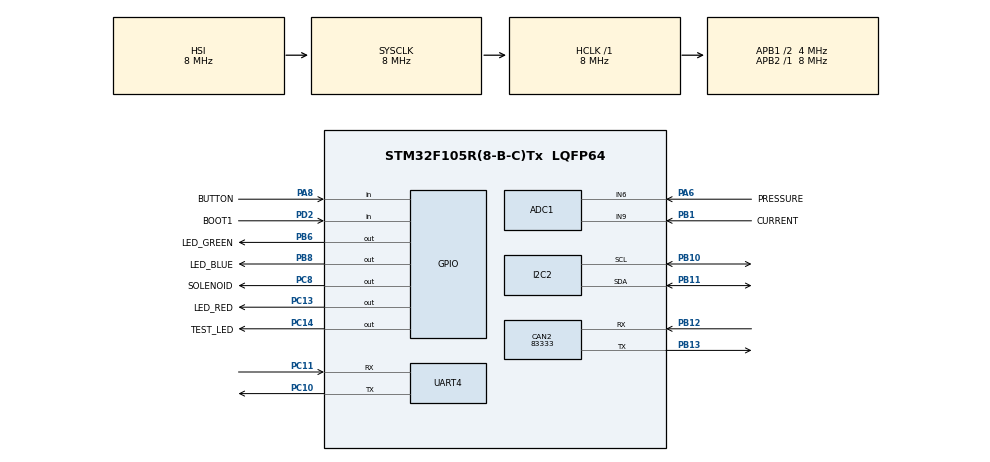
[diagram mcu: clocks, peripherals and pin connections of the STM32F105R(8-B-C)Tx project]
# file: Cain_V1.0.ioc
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ADC1.Channel-2\#ChannelRegularConversion=ADC_CHANNEL_6
ADC1.Channel-3\#ChannelRegularConversion=ADC_CHANNEL_9
ADC1.Channel-4\#ChannelRegularConversion=ADC_CHANNEL_TEMPSENSOR
ADC1.ExternalTrigConv=ADC_EXTERNALTRIGCONV_T3_TRGO
ADC1.NbrOfConversion=3
ADC1.NbrOfConversionFlag=1
ADC1.Rank-2\#ChannelRegularConversion=1
ADC1.Rank-3\#ChannelRegularConversion=2
ADC1.Rank-4\#ChannelRegularConversion=3
ADC1.SamplingTime-2\#ChannelRegularConversion=ADC_SAMPLETIME_55CYCLES_5
ADC1.SamplingTime-3\#ChannelRegularConversion=ADC_SAMPLETIME_55CYCLES_5
ADC1.SamplingTime-4\#ChannelRegularConversion=ADC_SAMPLETIME_55CYCLES_5
ADC1.master=1
CAN2.CalculateBaudRate=83333
CAN2.CalculateTimeBit=12000
CAN2.CalculateTimeQuantum=4000.0
Dma.ADC1.0.Direction=DMA_PERIPH_TO_MEMORY
Dma.ADC1.0.Instance=DMA1_Channel1
Dma.ADC1.0.MemDataAlignment=DMA_MDATAALIGN_HALFWORD
Dma.ADC1.0.MemInc=DMA_MINC_ENABLE
Dma.ADC1.0.Mode=DMA_CIRCULAR
Dma.ADC1.0.PeriphDataAlignment=DMA_PDATAALIGN_HALFWORD
Dma.ADC1.0.PeriphInc=DMA_PINC_DISABLE
Dma.ADC1.0.Priority=DMA_PRIORITY_HIGH
Dma.Request0=ADC1
Mcu.Family=STM32F1
Mcu.Name=STM32F105R(8-B-C)Tx
Mcu.Package=LQFP64
NVIC.ADC1_2_IRQn=true\:0\:0\:false\:false\:true\:true\:true\:true
NVIC.DMA1_Channel1_IRQn=true\:0\:0\:false\:false\:true\:false\:true\:true
NVIC.PriorityGroup=NVIC_PRIORITYGROUP_4
PA13.Mode=Trace_Asynchronous_SW
PA13.Signal=SYS_JTMS-SWDIO
PA14.Mode=Trace_Asynchronous_SW
PA14.Signal=SYS_JTCK-SWCLK
PA6.GPIO_Label=PRESSURE
PA6.Signal=ADCx_IN6
PA8.GPIO_Label=BUTTON
PA8.Signal=GPIO_Input
PB1.GPIO_Label=CURRENT
PB1.Signal=ADCx_IN9
PB10.Mode=I2C
PB10.Signal=I2C2_SCL
PB11.Mode=I2C
PB11.Signal=I2C2_SDA
PB12.Mode=CAN_Activate
PB12.Signal=CAN2_RX
PB13.Mode=CAN_Activate
PB13.Signal=CAN2_TX
PB3.Mode=Trace_Asynchronous_SW
PB3.Signal=SYS_TRACESWO
PB6.GPIO_Label=LED_GREEN
PB6.PinState=GPIO_PIN_SET
PB6.Signal=GPIO_Output
PB8.GPIO_Label=LED_BLUE
PB8.PinState=GPIO_PIN_SET
PB8.Signal=GPIO_Output
PC10.Mode=Asynchronous
PC10.Signal=UART4_TX
PC11.Mode=Asynchronous
PC11.Signal=UART4_RX
PC13-TAMPER-RTC.GPIO_Label=LED_RED
PC13-TAMPER-RTC.PinState=GPIO_PIN_SET
PC13-TAMPER-RTC.Signal=GPIO_Output
PC14-OSC32_IN.GPIO_Label=TEST_LED
PC14-OSC32_IN.Signal=GPIO_Output
PC8.GPIO_Label=SOLENOID
PC8.Signal=GPIO_Output
PD0-OSC_IN.Mode=HSE-External-Oscillator
PD0-OSC_IN.Signal=RCC_OSC_IN
PD1-OSC_OUT.Mode=HSE-External-Oscillator
PD1-OSC_OUT.Signal=RCC_OSC_OUT
PD2.GPIO_Label=BOOT1
PD2.Signal=GPIO_Input
ProjectManager.HeapSize=0x200
ProjectManager.StackSize=0x400
ProjectManager.TargetToolchain=STM32CubeIDE
RCC.ADCPresc=RCC_ADCPCLK2_DIV8
RCC.AHBFreq_Value=8000000
RCC.APB1CLKDivider=RCC_HCLK_DIV2
RCC.APB1Freq_Value=4000000
RCC.APB1TimFreq_Value=8000000
RCC.APB2Freq_Value=8000000
RCC.APB2TimFreq_Value=8000000
RCC.HCLKFreq_Value=8000000
RCC.PLLMUL=RCC_PLL_MUL9
RCC.PLLSourceVirtual=RCC_PLLSOURCE_HSE
RCC.SYSCLKFreq_VALUE=8000000
RCC.USBFreq_Value=48000000
SH.ADCx_IN6.0=ADC1_IN6,IN6
SH.ADCx_IN9.0=ADC1_IN9,IN9
TIM3.Period=99
TIM3.Prescaler=7199
TIM3.TIM_MasterOutputTrigger=TIM_TRGO_UPDATE
UART4.VirtualMode=Asynchronous
VP_ADC1_TempSens_Input.Mode=IN-TempSens
VP_TIM3_VS_ClockSourceINT.Mode=Internal
board=custom

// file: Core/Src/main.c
/* USER CODE BEGIN Header */
/**
  ******************************************************************************
  * @file           : main.c
  * @brief          : Main program body
  ******************************************************************************
  * @attention
  *
  * Copyright (c) 2025 STMicroelectronics.
  * All rights reserved.
  *
  * This software is licensed under terms that can be found in the LICENSE file
  * in the root directory of this software component.
  * If no LICENSE file comes with this software, it is provided AS-IS.
  *
  ******************************************************************************
  */
/* USER CODE END Header */
#include "main.h"

ADC_HandleTypeDef hadc1;
DMA_HandleTypeDef hdma_adc1;

CAN_HandleTypeDef hcan2;

I2C_HandleTypeDef hi2c2;

TIM_HandleTypeDef htim3;

UART_HandleTypeDef huart4;

void SystemClock_Config(void);
static void MX_GPIO_Init(void);
static void MX_DMA_Init(void);
static void MX_ADC1_Init(void);
static void MX_CAN2_Init(void);
static void MX_I2C2_Init(void);
static void MX_UART4_Init(void);
static void MX_TIM3_Init(void);

/* USER CODE BEGIN 0 */
volatile uint32_t count = 0;
/* USER CODE END 0 */

int main(void)
{

  /* MCU Configuration--------------------------------------------------------*/

  /* Reset of all peripherals, Initializes the Flash interface and the Systick. */
  HAL_Init();

  /* Configure the system clock */
  SystemClock_Config();

  /* Initialize all configured peripherals */
  MX_GPIO_Init();
  MX_DMA_Init();
  MX_ADC1_Init();
  MX_CAN2_Init();
  MX_I2C2_Init();
  MX_UART4_Init();
  MX_TIM3_Init();

  /* Infinite loop */
  /* USER CODE BEGIN WHILE */
  while (1)
  {

//	  HAL_GPIO_TogglePin(LED_RED_GPIO_Port ,LED_RED_Pin);
//	  HAL_Delay(500);
//	  HAL_GPIO_TogglePin(LED_GREEN_GPIO_Port ,LED_GREEN_Pin);
//	  HAL_Delay(500);
//	  HAL_GPIO_TogglePin(LED_BLUE_GPIO_Port ,LED_BLUE_Pin);
//	  HAL_Delay(500);
	  HAL_GPIO_TogglePin(SOLENOID_GPIO_Port ,SOLENOID_Pin);
	  HAL_Delay(100);
	  HAL_GPIO_TogglePin(SOLENOID_GPIO_Port ,SOLENOID_Pin);
	  HAL_Delay(100);
	  count = count + 1;

    /* USER CODE END WHILE */

  }
}

void SystemClock_Config(void)
{
  RCC_OscInitTypeDef RCC_OscInitStruct = {0};
  RCC_ClkInitTypeDef RCC_ClkInitStruct = {0};
  RCC_PeriphCLKInitTypeDef PeriphClkInit = {0};

  /** Initializes the RCC Oscillators according to the specified parameters
  * in the RCC_OscInitTypeDef structure.
  */
  RCC_OscInitStruct.OscillatorType = RCC_OSCILLATORTYPE_HSI;
  RCC_OscInitStruct.HSIState = RCC_HSI_ON;
  RCC_OscInitStruct.HSICalibrationValue = RCC_HSICALIBRATION_DEFAULT;
  RCC_OscInitStruct.PLL.PLLState = RCC_PLL_NONE;
  RCC_OscInitStruct.PLL2.PLL2State = RCC_PLL_NONE;
  if (HAL_RCC_OscConfig(&RCC_OscInitStruct) != HAL_OK)
  {
    Error_Handler();
  }

  /** Initializes the CPU, AHB and APB buses clocks
  */
  RCC_ClkInitStruct.ClockType = RCC_CLOCKTYPE_HCLK|RCC_CLOCKTYPE_SYSCLK
                              |RCC_CLOCKTYPE_PCLK1|RCC_CLOCKTYPE_PCLK2;
  RCC_ClkInitStruct.SYSCLKSource = RCC_SYSCLKSOURCE_HSI;
  RCC_ClkInitStruct.AHBCLKDivider = RCC_SYSCLK_DIV1;
  RCC_ClkInitStruct.APB1CLKDivider = RCC_HCLK_DIV2;
  RCC_ClkInitStruct.APB2CLKDivider = RCC_HCLK_DIV1;

  if (HAL_RCC_ClockConfig(&RCC_ClkInitStruct, FLASH_LATENCY_0) != HAL_OK)
  {
    Error_Handler();
  }
  PeriphClkInit.PeriphClockSelection = RCC_PERIPHCLK_ADC;
  PeriphClkInit.AdcClockSelection = RCC_ADCPCLK2_DIV8;
  if (HAL_RCCEx_PeriphCLKConfig(&PeriphClkInit) != HAL_OK)
  {
    Error_Handler();
  }

  /** Configure the Systick interrupt time
  */
  __HAL_RCC_PLLI2S_ENABLE();
}

static void MX_ADC1_Init(void)
{

  ADC_ChannelConfTypeDef sConfig = {0};

  /** Common config
  */
  hadc1.Instance = ADC1;
  hadc1.Init.ScanConvMode = ADC_SCAN_ENABLE;
  hadc1.Init.ContinuousConvMode = DISABLE;
  hadc1.Init.DiscontinuousConvMode = DISABLE;
  hadc1.Init.ExternalTrigConv = ADC_EXTERNALTRIGCONV_T3_TRGO;
  hadc1.Init.DataAlign = ADC_DATAALIGN_RIGHT;
  hadc1.Init.NbrOfConversion = 3;
  if (HAL_ADC_Init(&hadc1) != HAL_OK)
  {
    Error_Handler();
  }

  /** Configure Regular Channel
  */
  sConfig.Channel = ADC_CHANNEL_6;
  sConfig.Rank = ADC_REGULAR_RANK_1;
  sConfig.SamplingTime = ADC_SAMPLETIME_55CYCLES_5;
  if (HAL_ADC_ConfigChannel(&hadc1, &sConfig) != HAL_OK)
  {
    Error_Handler();
  }

  /** Configure Regular Channel
  */
  sConfig.Channel = ADC_CHANNEL_9;
  sConfig.Rank = ADC_REGULAR_RANK_2;
  if (HAL_ADC_ConfigChannel(&hadc1, &sConfig) != HAL_OK)
  {
    Error_Handler();
  }

  /** Configure Regular Channel
  */
  sConfig.Channel = ADC_CHANNEL_TEMPSENSOR;
  sConfig.Rank = ADC_REGULAR_RANK_3;
  if (HAL_ADC_ConfigChannel(&hadc1, &sConfig) != HAL_OK)
  {
    Error_Handler();
  }

}

static void MX_CAN2_Init(void)
{

  hcan2.Instance = CAN2;
  hcan2.Init.Prescaler = 16;
  hcan2.Init.Mode = CAN_MODE_NORMAL;
  hcan2.Init.SyncJumpWidth = CAN_SJW_1TQ;
  hcan2.Init.TimeSeg1 = CAN_BS1_1TQ;
  hcan2.Init.TimeSeg2 = CAN_BS2_1TQ;
  hcan2.Init.TimeTriggeredMode = DISABLE;
  hcan2.Init.AutoBusOff = DISABLE;
  hcan2.Init.AutoWakeUp = DISABLE;
  hcan2.Init.AutoRetransmission = DISABLE;
  hcan2.Init.ReceiveFifoLocked = DISABLE;
  hcan2.Init.TransmitFifoPriority = DISABLE;
  if (HAL_CAN_Init(&hcan2) != HAL_OK)
  {
    Error_Handler();
  }

}

static void MX_I2C2_Init(void)
{

  hi2c2.Instance = I2C2;
  hi2c2.Init.ClockSpeed = 100000;
  hi2c2.Init.DutyCycle = I2C_DUTYCYCLE_2;
  hi2c2.Init.OwnAddress1 = 0;
  hi2c2.Init.AddressingMode = I2C_ADDRESSINGMODE_7BIT;
  hi2c2.Init.DualAddressMode = I2C_DUALADDRESS_DISABLE;
  hi2c2.Init.OwnAddress2 = 0;
  hi2c2.Init.GeneralCallMode = I2C_GENERALCALL_DISABLE;
  hi2c2.Init.NoStretchMode = I2C_NOSTRETCH_DISABLE;
  if (HAL_I2C_Init(&hi2c2) != HAL_OK)
  {
    Error_Handler();
  }

}

static void MX_TIM3_Init(void)
{

  TIM_ClockConfigTypeDef sClockSourceConfig = {0};
  TIM_MasterConfigTypeDef sMasterConfig = {0};

  htim3.Instance = TIM3;
  htim3.Init.Prescaler = 7199;
  htim3.Init.CounterMode = TIM_COUNTERMODE_UP;
  htim3.Init.Period = 99;
  htim3.Init.ClockDivision = TIM_CLOCKDIVISION_DIV1;
  htim3.Init.AutoReloadPreload = TIM_AUTORELOAD_PRELOAD_DISABLE;
  if (HAL_TIM_Base_Init(&htim3) != HAL_OK)
  {
    Error_Handler();
  }
  sClockSourceConfig.ClockSource = TIM_CLOCKSOURCE_INTERNAL;
  if (HAL_TIM_ConfigClockSource(&htim3, &sClockSourceConfig) != HAL_OK)
  {
    Error_Handler();
  }
  sMasterConfig.MasterOutputTrigger = TIM_TRGO_UPDATE;
  sMasterConfig.MasterSlaveMode = TIM_MASTERSLAVEMODE_DISABLE;
  if (HAL_TIMEx_MasterConfigSynchronization(&htim3, &sMasterConfig) != HAL_OK)
  {
    Error_Handler();
  }

}

static void MX_UART4_Init(void)
{

  huart4.Instance = UART4;
  huart4.Init.BaudRate = 115200;
  huart4.Init.WordLength = UART_WORDLENGTH_8B;
  huart4.Init.StopBits = UART_STOPBITS_1;
  huart4.Init.Parity = UART_PARITY_NONE;
  huart4.Init.Mode = UART_MODE_TX_RX;
  huart4.Init.HwFlowCtl = UART_HWCONTROL_NONE;
  huart4.Init.OverSampling = UART_OVERSAMPLING_16;
  if (HAL_UART_Init(&huart4) != HAL_OK)
  {
    Error_Handler();
  }

}

static void MX_DMA_Init(void)
{

  /* DMA controller clock enable */
  __HAL_RCC_DMA1_CLK_ENABLE();

  /* DMA interrupt init */
  /* DMA1_Channel1_IRQn interrupt configuration */
  HAL_NVIC_SetPriority(DMA1_Channel1_IRQn, 0, 0);
  HAL_NVIC_EnableIRQ(DMA1_Channel1_IRQn);

}

static void MX_GPIO_Init(void)
{
  GPIO_InitTypeDef GPIO_InitStruct = {0};

  /* GPIO Ports Clock Enable */
  __HAL_RCC_GPIOC_CLK_ENABLE();
  __HAL_RCC_GPIOD_CLK_ENABLE();
  __HAL_RCC_GPIOA_CLK_ENABLE();
  __HAL_RCC_GPIOB_CLK_ENABLE();

  /*Configure GPIO pin Output Level */
  HAL_GPIO_WritePin(LED_RED_GPIO_Port, LED_RED_Pin, GPIO_PIN_SET);

  /*Configure GPIO pin Output Level */
  HAL_GPIO_WritePin(GPIOC, TEST_LED_Pin|SOLENOID_Pin, GPIO_PIN_RESET);

  /*Configure GPIO pin Output Level */
  HAL_GPIO_WritePin(GPIOB, LED_GREEN_Pin|LED_BLUE_Pin, GPIO_PIN_SET);

  /*Configure GPIO pins : LED_RED_Pin TEST_LED_Pin SOLENOID_Pin */
  GPIO_InitStruct.Pin = LED_RED_Pin|TEST_LED_Pin|SOLENOID_Pin;
  GPIO_InitStruct.Mode = GPIO_MODE_OUTPUT_PP;
  GPIO_InitStruct.Pull = GPIO_NOPULL;
  GPIO_InitStruct.Speed = GPIO_SPEED_FREQ_LOW;
  HAL_GPIO_Init(GPIOC, &GPIO_InitStruct);

  /*Configure GPIO pin : BUTTON_Pin */
  GPIO_InitStruct.Pin = BUTTON_Pin;
  GPIO_InitStruct.Mode = GPIO_MODE_INPUT;
  GPIO_InitStruct.Pull = GPIO_NOPULL;
  HAL_GPIO_Init(BUTTON_GPIO_Port, &GPIO_InitStruct);

  /*Configure GPIO pin : BOOT1_Pin */
  GPIO_InitStruct.Pin = BOOT1_Pin;
  GPIO_InitStruct.Mode = GPIO_MODE_INPUT;
  GPIO_InitStruct.Pull = GPIO_NOPULL;
  HAL_GPIO_Init(BOOT1_GPIO_Port, &GPIO_InitStruct);

  /*Configure GPIO pins : LED_GREEN_Pin LED_BLUE_Pin */
  GPIO_InitStruct.Pin = LED_GREEN_Pin|LED_BLUE_Pin;
  GPIO_InitStruct.Mode = GPIO_MODE_OUTPUT_PP;
  GPIO_InitStruct.Pull = GPIO_NOPULL;
  GPIO_InitStruct.Speed = GPIO_SPEED_FREQ_LOW;
  HAL_GPIO_Init(GPIOB, &GPIO_InitStruct);

}

void Error_Handler(void)
{
  __disable_irq();
  while (1)
  {
  }
}
